# MIMXRT1041 register map
Vendor: nxp.com; File version: 1.0
CPU: CM7 r0p1, little endian, MPU, FPU, VTOR, 4 interrupt priority bits
Registers are 32-bit, read-write, reset 0x0 unless marked. A register's access mark holds for its fields unless they carry their own. Offsets are from the block's base; [hi:lo] are bit positions; 'fields as' and 'values as' point back to an identical list.

## IOMUXC_SNVS
Base 0x400A8000; register names take the prefix IOMUXC_SNVS_
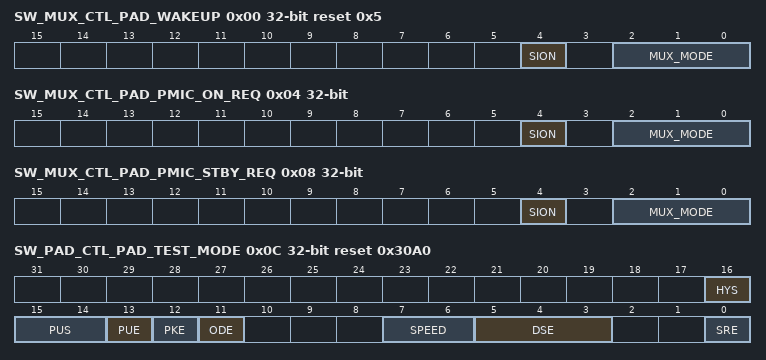
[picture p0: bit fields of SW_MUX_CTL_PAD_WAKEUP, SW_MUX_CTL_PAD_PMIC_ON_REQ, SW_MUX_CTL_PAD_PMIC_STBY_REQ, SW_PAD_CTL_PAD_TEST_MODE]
0x00 SW_MUX_CTL_PAD_WAKEUP reset 0x5 — SW_MUX_CTL_PAD_WAKEUP SW MUX Control Register
  [4] SION — Software Input On Field.
    0=DISABLED (Input Path is determined by functionality); 1=ENABLED (Force input path of pad WAKEUP)
  [2:0] MUX_MODE — MUX Mode Select Field.
    5=ALT5 (Select mux mode: ALT5 mux port: GPIO5_IO00 of instance: gpio5); 7=ALT7 (Select mux mode: ALT7 mux port: NMI of instance: CM7)
0x04 SW_MUX_CTL_PAD_PMIC_ON_REQ — SW_MUX_CTL_PAD_PMIC_ON_REQ SW MUX Control Register
  [4] SION — Software Input On Field.
    0=DISABLED (Input Path is determined by functionality); 1=ENABLED (Force input path of pad PMIC_ON_REQ)
  [2:0] MUX_MODE — MUX Mode Select Field.
    0=ALT0 (Select mux mode: ALT0 mux port: SNVS_PMIC_ON_REQ of instance: snvs); 5=ALT5 (Select mux mode: ALT5 mux port: GPIO5_IO01 of instance: gpio5)
0x08 SW_MUX_CTL_PAD_PMIC_STBY_REQ — SW_MUX_CTL_PAD_PMIC_STBY_REQ SW MUX Control Register
  [4] SION — Software Input On Field.
    0=DISABLED (Input Path is determined by functionality); 1=ENABLED (Force input path of pad PMIC_STBY_REQ)
  [2:0] MUX_MODE — MUX Mode Select Field.
    0=ALT0 (Select mux mode: ALT0 mux port: CCM_PMIC_STBY_REQ of instance: ccm); 5=ALT5 (Select mux mode: ALT5 mux port: GPIO5_IO02 of instance: gpio5)
0x0C SW_PAD_CTL_PAD_TEST_MODE reset 0x30A0 — SW_PAD_CTL_PAD_TEST_MODE SW PAD Control Register
  [16] HYS — Hyst. Enable Field
    0=HYS_0_Hysteresis_Disabled (Hysteresis Disabled (CMOS input)); 1=HYS_1_Hysteresis_Enabled (Hysteresis Enabled (Schmitt Trigger input))
  [15:14] PUS — Pull Up / Down Config. Field Controls signals to select pull-up or pull-down internal resistance strength.
    0=PUS_0_100K_Ohm_Pull_Down (100K Ohm Pull Down); 1=PUS_1_47K_Ohm_Pull_Up (47K Ohm Pull Up); 2=PUS_2_100K_Ohm_Pull_Up (100K Ohm Pull Up); 3=PUS_3_22K_Ohm_Pull_Up (22K Ohm Pull Up)
  [13] PUE — Pull / Keep Select Field Control signal to enable internal pull-up/down resistors or pad keeper functionality.
    0=PUE_0_Keeper (Keep the previous output value when the output driver is disabled.); 1=PUE_1_Pull (Pull-up or pull-down (determined by PUS field).)
  [12] PKE — Pull / Keep Enable Field
    0=PKE_0_Pull_Keeper_Disabled (Pull/Keeper Disabled); 1=PKE_1_Pull_Keeper_Enabled (Pull/Keeper Enabled)
  [11] ODE — Open Drain Enable Field
    0=ODE_0_Open_Drain_Disabled (Open Drain Disabled (Output is CMOS)); 1=ODE_1_Open_Drain_Enabled (Open Drain Enabled (Output is Open Drain))
  [7:6] SPEED ro
    2=Medium (100MHz)
  [5:3] DSE — Drive Strength Field
    0=HI-Z; 1=Dual/Single voltage: 262/260 Ohm @ 1.8V, 247/157 Ohm @ 3.3V; 2=Dual/Single voltage: 134/130 Ohm @ 1.8V, 126/78 Ohm @ 3.3V; 3=Dual/Single voltage: 88/88 Ohm @ 1.8V, 84/53 Ohm @ 3.3V; 4=Dual/Single voltage: 62/65 Ohm @ 1.8V, 57/39 Ohm @ 3.3V; 5=Dual/Single voltage: 51/52 Ohm @ 1.8V, 47/32 Ohm @ 3.3V; 6=Dual/Single voltage: 43/43 Ohm @ 1.8V, 40/26 Ohm @ 3.3V; 7=Dual/Single voltage: 37/37 Ohm @ 1.8V, 34/23 Ohm @ 3.3V
  [0] SRE — Slew Rate Field
    0=SRE_0_Slow_Slew_Rate (Slow Slew Rate); 1=SRE_1_Fast_Slew_Rate (Fast Slew Rate)
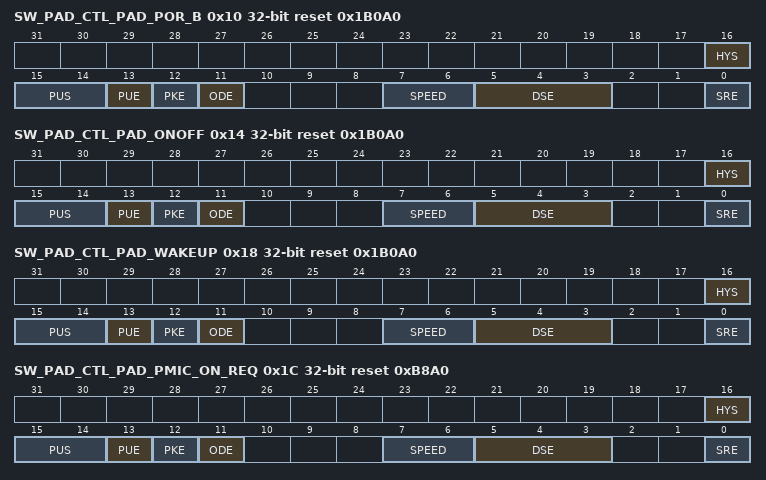
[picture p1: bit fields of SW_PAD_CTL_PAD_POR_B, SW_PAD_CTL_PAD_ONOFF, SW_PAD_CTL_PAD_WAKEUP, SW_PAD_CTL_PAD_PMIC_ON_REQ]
0x10 SW_PAD_CTL_PAD_POR_B reset 0x1B0A0 — SW_PAD_CTL_PAD_POR_B SW PAD Control Register
  fields as SW_PAD_CTL_PAD_TEST_MODE
0x14 SW_PAD_CTL_PAD_ONOFF reset 0x1B0A0 — SW_PAD_CTL_PAD_ONOFF SW PAD Control Register
  fields as SW_PAD_CTL_PAD_TEST_MODE
0x18 SW_PAD_CTL_PAD_WAKEUP reset 0x1B0A0 — SW_PAD_CTL_PAD_WAKEUP SW PAD Control Register
  fields as SW_PAD_CTL_PAD_TEST_MODE
0x1C SW_PAD_CTL_PAD_PMIC_ON_REQ reset 0xB8A0 — SW_PAD_CTL_PAD_PMIC_ON_REQ SW PAD Control Register
  fields as SW_PAD_CTL_PAD_TEST_MODE
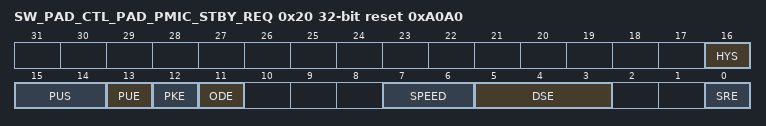
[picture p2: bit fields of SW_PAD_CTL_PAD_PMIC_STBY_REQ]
0x20 SW_PAD_CTL_PAD_PMIC_STBY_REQ reset 0xA0A0 — SW_PAD_CTL_PAD_PMIC_STBY_REQ SW PAD Control Register
  fields as SW_PAD_CTL_PAD_TEST_MODE
